# RA register map
Vendor: Renesas; Series: All Chips; File version: x.xx
Registers are 32-bit, read-write, reset 0x0 unless marked. A register's access mark holds for its fields unless they carry their own. Offsets are from the block's base; [hi:lo] are bit positions; lines under a group give offsets from that group; {n}, {i} and the like mark numbered series.

## R_ELC — Event Link Controller
Base 0x40041000
0x00 ELCR 8-bit — Event Link Controller Register
  [7] ELCON — All Event Link Enable
    0=ELC function is disabled; 1=ELC function is enabled
{0x2+2i} ELSEGR[{i}] (i=0..1) group — Event Link Software Event Generation Register
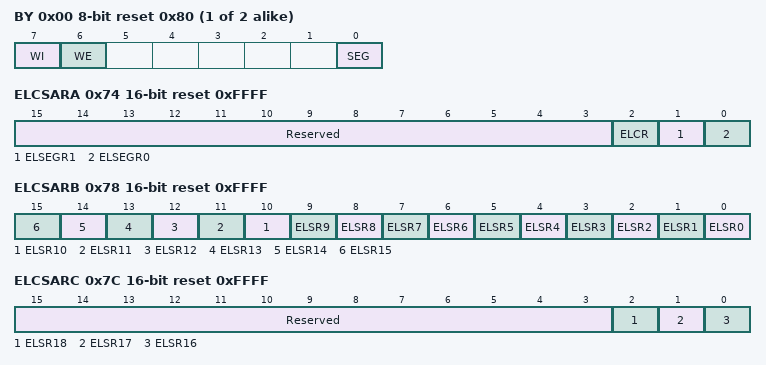
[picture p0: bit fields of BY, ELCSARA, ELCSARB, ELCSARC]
  0x00 BY 8-bit reset 0x80 — Event Link Software Event Generation Register
    [7] WI wo — ELSEGR Register Write Disable
      0=Write to ELSEGR register is enabled; 1=Write to ELSEGR register is disabled
    [6] WE — SEG Bit Write Enable
      0=Write to SEG bit is disabled; 1=Write to SEG bit is enabled
    [0] SEG wo — Software Event Generation
      0=Normal operation; 1=Software event is generated
{0x10+4i} ELSR[{i}] (i=0..22) group — Event Link Setting Register {i}
  0x00 HA 16-bit — Event Link Setting Register
    [8:0] ELS — Event Link Select
      0=Event output to the corresponding peripheral module is disabled; other=others (Set the number for the event signal to be linked.)
0x74 ELCSARA 16-bit reset 0xFFFF — Event Link Controller Security Attribution Register A
  [15:3] Reserved — These bits are read as 1111111111111. The write value should be 1111111111111.
  [2] ELCR — Event Link Controller RegisterSecurity Attribution
    0=Secure; 1=NonSecure
  [1] ELSEGR1 — Event Link Software Event Generation Register 1Security Attribution
    0=Secure; 1=NonSecure
  [0] ELSEGR0 — Event Link Software Event Generation Register 0 Security Attribution
    0=Secure; 1=NonSecure
0x78 ELCSARB 16-bit reset 0xFFFF — Event Link Controller Security Attribution Register B
  [all] fields
    0=Secure; 1=NonSecure
  [n] ELSR{n} (n=0..15) — Event Link Setting Register {n}Security Attribution
0x7C ELCSARC 16-bit reset 0xFFFF — Event Link Controller Security Attribution Register C
  [15:3] Reserved — These bits are read as 1111111111111. The write value should be 1111111111111.
  [2] ELSR18 — Event Link Setting Register 18Security Attribution
    0=Secure; 1=NonSecure
  [1] ELSR17 — Event Link Setting Register 17Security Attribution
    0=Secure; 1=NonSecure
  [0] ELSR16 — Event Link Setting Register 16Security Attribution
    0=Secure; 1=NonSecure

## R_ETHERC_EPTPC_CFG — Ethernet PTP Configuration
Base 0x40064500
0x00 PTRSTR — EPTPC Reset Register
  [0] RESET — EPTPC Software Reset
    0=Do not reset the EPTPC; 1=Reset the EPTPC. Do not access the EPTPC-related registers other than this register while a software reset is being issued.
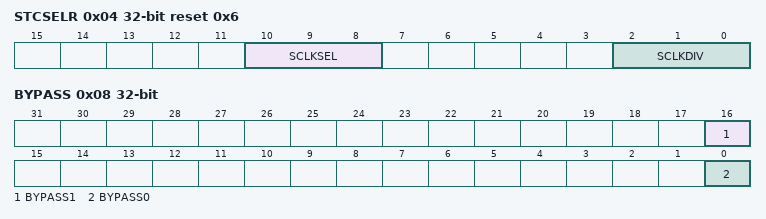
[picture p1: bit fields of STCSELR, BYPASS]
0x04 STCSELR reset 0x6 — STCA Clock Select Register
  [10:8] SCLKSEL — STCA Clock Select
    0=PCLKA clock divided by 1 to 6; 2=Input clock from the REF50CK0 pin; 3=Input clock from the REF50CK1 pin; other=others (Settings other than above are prohibited.)
  [2:0] SCLKDIV — PCLKA Clock Frequency Division
    1=1; {v}=1/{v} (v=2..6); other=others (Settings other than above are prohibited.)
0x08 BYPASS — Bypass 1588 module Register
  [16] BYPASS1 — Bypass 1588 module for Ether 1ch
    0=to use 1588 module for Ether 1ch; 1=to bypass 1588 module for Ether 1ch
  [0] BYPASS0 — Bypass 1588 module for Ether 0ch
    0=to use 1588 module for Ether 0ch; 1=to bypass 1588 module for Ether 0ch

## R_FACI_HP_CMD — Flash Application Command Interface Command-Issuing Area
Base 0x407E0000
0x00 FACI_CMD16 16-bit — FACI Command Issuing Area (halfword access)
0x00 FACI_CMD8 8-bit (alternate view of FACI_CMD16) — FACI Command Issuing Area (halfword access)

## R_CTSUTRIM — CTSU Trimming Registers
Base 0x407EC000
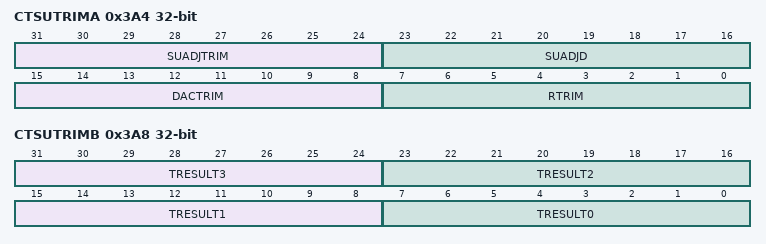
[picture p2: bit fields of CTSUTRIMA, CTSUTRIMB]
0x3A4 CTSUTRIMA — CTSU Trimming Register A
  [31:24] SUADJTRIM — Coefficient of variation for the reference load resistance (120k)
  [23:16] SUADJD — CTSU SUCLK Frequency Adjustment
  [15:8] DACTRIM — Linearity Adjustment of Offset Current
  [7:0] RTRIM — CTSU Reference Resistance Adjustment
0x3A8 CTSUTRIMB — CTSU Trimming Register B
  [31:24] TRESULT3 — Coefficient of variation for the reference load resistance (60k)
  [23:16] TRESULT2 — Coefficient of variation for the reference load resistance (30k)
  [15:8] TRESULT1 — Coefficient of variation for the reference load resistance (15k)
  [7:0] TRESULT0 — Coefficient of variation for the reference load resistance (7.5k)
